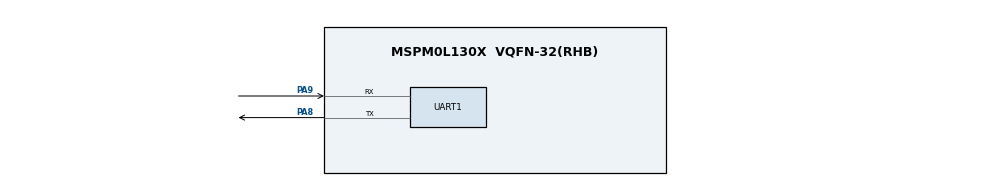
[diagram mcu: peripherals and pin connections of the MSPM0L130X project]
/**
 * @cliArgs --device "MSPM0L130X" --package "VQFN-32(RHB)" --part "Default" --product "mspm0_sdk@2.01.00.03"
 * @versions {"tool":"1.20.0+3587"}
 */

/**
 * Import the modules used in this configuration.
 */
const ADC12  = scripting.addModule("/ti/driverlib/ADC12", {}, false);
const ADC121 = ADC12.addInstance();
const SYSCTL = scripting.addModule("/ti/driverlib/SYSCTL");
const UART   = scripting.addModule("/ti/driverlib/UART", {}, false);
const UART1  = UART.addInstance();

/**
 * Write custom configuration values to the imported modules.
 */
ADC121.$name                      = "ADC12_0";
ADC121.sampClkDiv                 = "DL_ADC12_CLOCK_DIVIDE_8";
ADC121.sampleMode                 = "DL_ADC12_SAMPLING_SOURCE_MANUAL";
ADC121.powerDownMode              = "DL_ADC12_POWER_DOWN_MODE_MANUAL";
ADC121.samplingOperationMode      = "sequence";
ADC121.endAdd                     = 1;
ADC121.adcMem1chansel             = "DL_ADC12_INPUT_CHAN_1";
ADC121.peripheral.adcPin0.$assign = "PA27";
ADC121.adcPin0Config.$name        = "ti_driverlib_gpio_GPIOPinGeneric0";
ADC121.adcPin1Config.$name        = "ti_driverlib_gpio_GPIOPinGeneric3";

const Board = scripting.addModule("/ti/driverlib/Board", {}, false);


UART1.$name                    = "UART_0";
UART1.targetBaudRate           = 115200;
UART1.peripheral.rxPin.$assign = "PA9";
UART1.peripheral.txPin.$assign = "PA8";
UART1.txPinConfig.$name        = "ti_driverlib_gpio_GPIOPinGeneric1";
UART1.rxPinConfig.$name        = "ti_driverlib_gpio_GPIOPinGeneric2";

/**
 * Pinmux solution for unlocked pins/peripherals. This ensures that minor changes to the automatic solver in a future
 * version of the tool will not impact the pinmux you originally saw.  These lines can be completely deleted in order to
 * re-solve from scratch.
 */
ADC121.peripheral.$suggestSolution         = "ADC0";
ADC121.peripheral.adcPin1.$suggestSolution = "PA26";
Board.peripheral.$suggestSolution          = "DEBUGSS";
Board.peripheral.swclkPin.$suggestSolution = "PA20";
Board.peripheral.swdioPin.$suggestSolution = "PA19";
SYSCTL.peripheral.$suggestSolution         = "SYSCTL";
UART1.peripheral.$suggestSolution          = "UART0";
